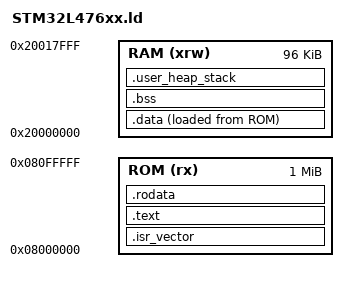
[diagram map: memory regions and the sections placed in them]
ENTRY(Reset_Handler)

_Min_Heap_Size  = 0x400;
_Min_Stack_Size = 0x200;

MEMORY {
    ROM (rx)  : ORIGIN = 0x08000000, LENGTH = 1024K
    RAM (xrw) : ORIGIN = 0x20000000, LENGTH = 96K
}

_estack = ORIGIN(RAM) + LENGTH(RAM);

SECTIONS {

    /* Vector table at start of flash */
    .isr_vector :
    {
        . = ALIGN(4);
        KEEP(*(.isr_vector))
        . = ALIGN(4);
    } > ROM

    .text :
    {
        . = ALIGN(4);
        *(.text)
        *(.text*)
        . = ALIGN(4);
    } > ROM

    .rodata :
    {
        . = ALIGN(4);
        *(.rodata)
        *(.rodata*)
        . = ALIGN(4);
    } > ROM

    .data :
    {
        . = ALIGN(4);
        _sdata = .;
        *(.data)
        *(.data*)
        . = ALIGN(4);
        _edata = .;
    } > RAM AT > ROM

    _sidata = LOADADDR(.data);

    .bss :
    {
        . = ALIGN(4);
        _sbss = .;
        *(.bss)
        *(.bss*)
        *(COMMON)
        . = ALIGN(4);
        _ebss = .;
    } > RAM

    .user_heap_stack :
    {
        . = ALIGN(4);
        _ssystem_ram = .;
        . = . + _Min_Heap_Size;
        . = . + _Min_Stack_Size;
        . = ALIGN(4);
        _esystem_ram = .;
    } > RAM
}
